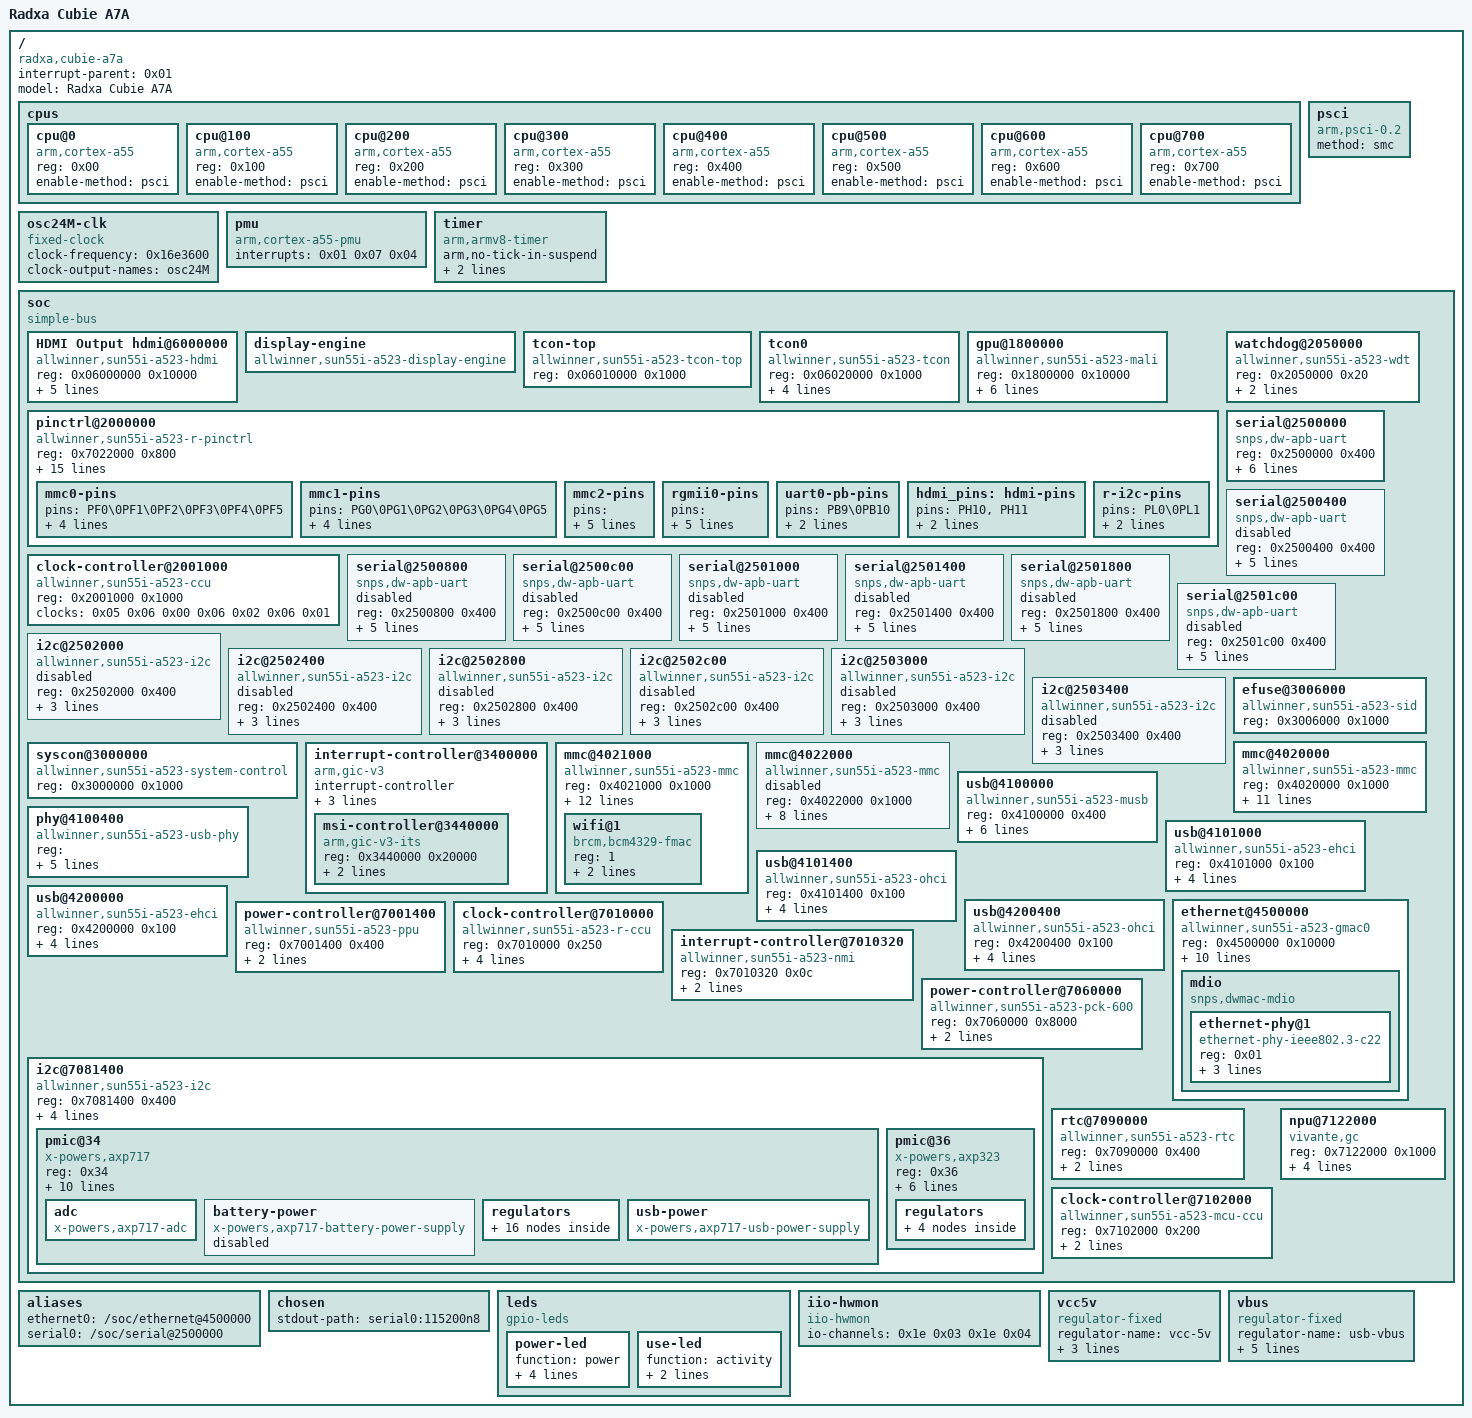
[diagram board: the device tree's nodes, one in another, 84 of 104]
/dts-v1/;

/ {
	interrupt-parent = <0x01>;
	#address-cells = <0x02>;
	#size-cells = <0x02>;
	model = "Radxa Cubie A7A";
	compatible = "radxa,cubie-a7a\0allwinner,sun60i-a733";

	cpus {
		#address-cells = <0x01>;
		#size-cells = <0x00>;

		cpu@0 {
			compatible = "arm,cortex-a55";
			device_type = "cpu";
			reg = <0x00>;
			enable-method = "psci";
		};

		cpu@100 {
			compatible = "arm,cortex-a55";
			device_type = "cpu";
			reg = <0x100>;
			enable-method = "psci";
		};

		cpu@200 {
			compatible = "arm,cortex-a55";
			device_type = "cpu";
			reg = <0x200>;
			enable-method = "psci";
		};

		cpu@300 {
			compatible = "arm,cortex-a55";
			device_type = "cpu";
			reg = <0x300>;
			enable-method = "psci";
		};

		cpu@400 {
			compatible = "arm,cortex-a55";
			device_type = "cpu";
			reg = <0x400>;
			enable-method = "psci";
		};

		cpu@500 {
			compatible = "arm,cortex-a55";
			device_type = "cpu";
			reg = <0x500>;
			enable-method = "psci";
		};

		cpu@600 {
			compatible = "arm,cortex-a55";
			device_type = "cpu";
			reg = <0x600>;
			enable-method = "psci";
		};

		cpu@700 {
			compatible = "arm,cortex-a55";
			device_type = "cpu";
			reg = <0x700>;
			enable-method = "psci";
		};
	};

	osc24M-clk {
		#clock-cells = <0x00>;
		compatible = "fixed-clock";
		clock-frequency = <0x16e3600>;
		clock-output-names = "osc24M";
		phandle = <0x05>;
	};

	pmu {
		compatible = "arm,cortex-a55-pmu";
		interrupts = <0x01 0x07 0x04>;
	};

	psci {
		compatible = "arm,psci-0.2";
		method = "smc";
	};

	timer {
		compatible = "arm,armv8-timer";
		arm,no-tick-in-suspend;
		interrupts = <0x01 0x0d 0x04 0x01 0x0e 0x04 0x01 0x0b 0x04 0x01 0x0a 0x04>;
	};

	soc {
		compatible = "simple-bus";
		#address-cells = <1>;
		#size-cells = <1>;
		ranges = <0x00 0x00 0x00 0x40000000>;

	HDMI Output
        hdmi@6000000 {
            compatible = "allwinner,sun55i-a523-hdmi";
            reg = <0x06000000 0x10000>;
            interrupts = <0 48 4>;
            clocks = <&ccu 144>;
            resets = <&ccu 96>;
            status = "okay";
            vdd-supply = <&vcc_hdmi>;
            pinctrl-names = "default";
            pinctrl-0 = <&hdmi_pins>;
        };

        display-engine {
            compatible = "allwinner,sun55i-a523-display-engine";
            status = "okay";
        };

        tcon-top {
            compatible = "allwinner,sun55i-a523-tcon-top";
            reg = <0x06010000 0x1000>;
            status = "okay";
        };

        tcon0 {
            compatible = "allwinner,sun55i-a523-tcon";
            reg = <0x06020000 0x1000>;
            interrupts = <0 49 4>;
            clocks = <&ccu 145>;
            resets = <&ccu 97>;
            status = "okay";
            vdd-supply = <&vcc_hdmi>;
		};
		
		gpu@1800000 {
			compatible = "allwinner,sun55i-a523-mali\0arm,mali-valhall-jm";
			reg = <0x1800000 0x10000>;
			interrupts = <0x00 0x75 0x04 0x00 0x76 0x04 0x00 0x77 0x04>;
			interrupt-names = "job\0mmu\0gpu";
			clocks = <0x02 0x33 0x02 0x34>;
			clock-names = "core\0bus";
			power-domains = <0x03 0x01>;
			resets = <0x02 0x06>;
			status = "okay";
			mali-supply = <0x04>;
		};

		pinctrl@2000000 {
			compatible = "allwinner,sun55i-a523-pinctrl";
			reg = <0x2000000 0x800>;
			interrupts = <0x00 0x45 0x04 0x00 0x47 0x04 0x00 0x49 0x04 0x00 0x4b 0x04 0x00 0x4d 0x04 0x00 0x4f 0x04 0x00 0x51 0x04 0x00 0x53 0x04 0x00 0x55 0x04 0x00 0x8c 0x04>;
			clocks = <0x02 0x2b 0x05 0x06 0x00>;
			clock-names = "apb\0hosc\0losc";
			gpio-controller;
			#gpio-cells = <0x03>;
			interrupt-controller;
			#interrupt-cells = <0x03>;
			vcc-pb-supply = <0x07>;
			vcc-pc-supply = <0x08>;
			vcc-pd-supply = <0x07>;
			vcc-pe-supply = <0x09>;
			vcc-pf-supply = <0x07>;
			vcc-pg-supply = <0x0a>;
			vcc-ph-supply = <0x07>;
			vcc-pi-supply = <0x07>;
			vcc-pj-supply = <0x0b>;
			vcc-pk-supply = <0x08>;
			phandle = <0x0e>;

			mmc0-pins {
				pins = "PF0\0PF1\0PF2\0PF3\0PF4\0PF5";
				allwinner,pinmux = <0x02>;
				function = "mmc0";
				drive-strength = <0x1e>;
				bias-pull-up;
				phandle = <0x0d>;
			};

			mmc1-pins {
				pins = "PG0\0PG1\0PG2\0PG3\0PG4\0PG5";
				allwinner,pinmux = <0x02>;
				function = "mmc1";
				drive-strength = <0x1e>;
				bias-pull-up;
				phandle = <0x0f>;
			};

			mmc2-pins {
				pins = "PC0\0PC1\0PC5\0PC6\0PC8\0PC9\0PC10\0PC11\0PC13\0PC14\0PC15\0PC16";
				allwinner,pinmux = <0x03>;
				function = "mmc2";
				drive-strength = <0x1e>;
				bias-pull-up;
				phandle = <0x10>;
			};

			rgmii0-pins {
				pins = "PH0\0PH1\0PH2\0PH3\0PH4\0PH5\0PH6\0PH7\0PH9\0PH10\0PH14\0PH15\0PH16\0PH17\0PH18";
				allwinner,pinmux = <0x05>;
				function = "gmac0";
				drive-strength = <0x28>;
				bias-disable;
				phandle = <0x14>;
			};

			uart0-pb-pins {
				pins = "PB9\0PB10";
				allwinner,pinmux = <0x02>;
				function = "uart0";
				phandle = <0x0c>;
			};
		};

		clock-controller@2001000 {
			compatible = "allwinner,sun55i-a523-ccu";
			reg = <0x2001000 0x1000>;
			clocks = <0x05 0x06 0x00 0x06 0x02 0x06 0x01>;
			clock-names = "hosc\0losc\0iosc\0losc-fanout";
			#clock-cells = <0x01>;
			#reset-cells = <0x01>;
			phandle = <0x02>;
		};

		watchdog@2050000 {
			compatible = "allwinner,sun55i-a523-wdt";
			reg = <0x2050000 0x20>;
			interrupts = <0x00 0x3f 0x04>;
			clocks = <0x05 0x06 0x00>;
			clock-names = "hosc\0losc";
			status = "okay";
		};

		serial@2500000 {
			compatible = "snps,dw-apb-uart";
			reg = <0x2500000 0x400>;
			interrupts = <0x00 0x02 0x04>;
			reg-shift = <0x02>;
			reg-io-width = <0x04>;
			clocks = <0x02 0x5b>;
			resets = <0x02 0x17>;
			status = "okay";
			pinctrl-names = "default";
			pinctrl-0 = <0x0c>;
		};

		serial@2500400 {
			compatible = "snps,dw-apb-uart";
			reg = <0x2500400 0x400>;
			interrupts = <0x00 0x03 0x04>;
			reg-shift = <0x02>;
			reg-io-width = <0x04>;
			clocks = <0x02 0x5c>;
			resets = <0x02 0x18>;
			status = "disabled";
		};

		serial@2500800 {
			compatible = "snps,dw-apb-uart";
			reg = <0x2500800 0x400>;
			interrupts = <0x00 0x04 0x04>;
			reg-shift = <0x02>;
			reg-io-width = <0x04>;
			clocks = <0x02 0x5d>;
			resets = <0x02 0x19>;
			status = "disabled";
		};

		serial@2500c00 {
			compatible = "snps,dw-apb-uart";
			reg = <0x2500c00 0x400>;
			interrupts = <0x00 0x05 0x04>;
			reg-shift = <0x02>;
			reg-io-width = <0x04>;
			clocks = <0x02 0x5e>;
			resets = <0x02 0x1a>;
			status = "disabled";
		};

		serial@2501000 {
			compatible = "snps,dw-apb-uart";
			reg = <0x2501000 0x400>;
			interrupts = <0x00 0x06 0x04>;
			reg-shift = <0x02>;
			reg-io-width = <0x04>;
			clocks = <0x02 0x5f>;
			resets = <0x02 0x1b>;
			status = "disabled";
		};

		serial@2501400 {
			compatible = "snps,dw-apb-uart";
			reg = <0x2501400 0x400>;
			interrupts = <0x00 0x07 0x04>;
			reg-shift = <0x02>;
			reg-io-width = <0x04>;
			clocks = <0x02 0x60>;
			resets = <0x02 0x1c>;
			status = "disabled";
		};

		serial@2501800 {
			compatible = "snps,dw-apb-uart";
			reg = <0x2501800 0x400>;
			interrupts = <0x00 0x08 0x04>;
			reg-shift = <0x02>;
			reg-io-width = <0x04>;
			clocks = <0x02 0x61>;
			resets = <0x02 0x1d>;
			status = "disabled";
		};

		serial@2501c00 {
			compatible = "snps,dw-apb-uart";
			reg = <0x2501c00 0x400>;
			interrupts = <0x00 0x09 0x04>;
			reg-shift = <0x02>;
			reg-io-width = <0x04>;
			clocks = <0x02 0x62>;
			resets = <0x02 0x1e>;
			status = "disabled";
		};

		i2c@2502000 {
			compatible = "allwinner,sun55i-a523-i2c\0allwinner,sun8i-v536-i2c\0allwinner,sun6i-a31-i2c";
			reg = <0x2502000 0x400>;
			interrupts = <0x00 0x0a 0x04>;
			clocks = <0x02 0x63>;
			resets = <0x02 0x1f>;
			status = "disabled";
			#address-cells = <0x01>;
			#size-cells = <0x00>;
		};

		i2c@2502400 {
			compatible = "allwinner,sun55i-a523-i2c\0allwinner,sun8i-v536-i2c\0allwinner,sun6i-a31-i2c";
			reg = <0x2502400 0x400>;
			interrupts = <0x00 0x0b 0x04>;
			clocks = <0x02 0x64>;
			resets = <0x02 0x20>;
			status = "disabled";
			#address-cells = <0x01>;
			#size-cells = <0x00>;
		};

		i2c@2502800 {
			compatible = "allwinner,sun55i-a523-i2c\0allwinner,sun8i-v536-i2c\0allwinner,sun6i-a31-i2c";
			reg = <0x2502800 0x400>;
			interrupts = <0x00 0x0c 0x04>;
			clocks = <0x02 0x65>;
			resets = <0x02 0x21>;
			status = "disabled";
			#address-cells = <0x01>;
			#size-cells = <0x00>;
		};

		i2c@2502c00 {
			compatible = "allwinner,sun55i-a523-i2c\0allwinner,sun8i-v536-i2c\0allwinner,sun6i-a31-i2c";
			reg = <0x2502c00 0x400>;
			interrupts = <0x00 0x0d 0x04>;
			clocks = <0x02 0x66>;
			resets = <0x02 0x22>;
			status = "disabled";
			#address-cells = <0x01>;
			#size-cells = <0x00>;
		};

		i2c@2503000 {
			compatible = "allwinner,sun55i-a523-i2c\0allwinner,sun8i-v536-i2c\0allwinner,sun6i-a31-i2c";
			reg = <0x2503000 0x400>;
			interrupts = <0x00 0x0e 0x04>;
			clocks = <0x02 0x67>;
			resets = <0x02 0x23>;
			status = "disabled";
			#address-cells = <0x01>;
			#size-cells = <0x00>;
		};

		i2c@2503400 {
			compatible = "allwinner,sun55i-a523-i2c\0allwinner,sun8i-v536-i2c\0allwinner,sun6i-a31-i2c";
			reg = <0x2503400 0x400>;
			interrupts = <0x00 0x0f 0x04>;
			clocks = <0x02 0x68>;
			resets = <0x02 0x24>;
			status = "disabled";
			#address-cells = <0x01>;
			#size-cells = <0x00>;
		};

		syscon@3000000 {
			compatible = "allwinner,sun55i-a523-system-control\0allwinner,sun50i-a64-system-control";
			reg = <0x3000000 0x1000>;
			#address-cells = <0x01>;
			#size-cells = <0x01>;
			ranges;
			phandle = <0x15>;
		};

		efuse@3006000 {
			compatible = "allwinner,sun55i-a523-sid\0allwinner,sun50i-a64-sid";
			reg = <0x3006000 0x1000>;
			#address-cells = <0x01>;
			#size-cells = <0x01>;
		};

		interrupt-controller@3400000 {
			compatible = "arm,gic-v3";
			#address-cells = <0x01>;
			#interrupt-cells = <0x03>;
			#size-cells = <0x01>;
			ranges;
			interrupt-controller;
			reg = <0x3400000 0x10000 0x3460000 0x100000>;
			interrupts = <0x01 0x09 0x04>;
			dma-noncoherent;
			phandle = <0x01>;

			msi-controller@3440000 {
				compatible = "arm,gic-v3-its";
				reg = <0x3440000 0x20000>;
				msi-controller;
				#msi-cells = <0x01>;
				dma-noncoherent;
			};
		};

		mmc@4020000 {
			compatible = "allwinner,sun55i-a523-mmc\0allwinner,sun20i-d1-mmc";
			reg = <0x4020000 0x1000>;
			clocks = <0x02 0x58 0x02 0x54>;
			clock-names = "ahb\0mmc";
			resets = <0x02 0x13>;
			reset-names = "ahb";
			interrupts = <0x00 0x28 0x04>;
			pinctrl-names = "default";
			pinctrl-0 = <0x0d>;
			status = "okay";
			max-frequency = <0x8f0d180>;
			cap-sd-highspeed;
			cap-mmc-highspeed;
			cap-sdio-irq;
			#address-cells = <0x01>;
			#size-cells = <0x00>;
			vmmc-supply = <0x07>;
			cd-gpios = <0x0e 0x05 0x06 0x11>;
			bus-width = <0x04>;
		};

			Wi-Fi 6 via SDIO (Quectel FCU760K)
        mmc@4021000 {
            compatible = "allwinner,sun55i-a523-mmc", "allwinner,sun20i-d1-mmc";
            reg = <0x4021000 0x1000>;
            clocks = <&ccu 89>, <&ccu 85>;
            clock-names = "ahb", "mmc";
            resets = <&ccu 20>;
            reset-names = "ahb";
            interrupts = <0 41 4>;
            pinctrl-names = "default";
            pinctrl-0 = <&mmc1_pins>;
            status = "okay";
            max-frequency = <0x8f0d180>;
            cap-sd-highspeed;
            cap-mmc-highspeed;
            cap-sdio-irq;
            bus-width = <4>;
            non-removable;
            keep-power-in-suspend;
            vmmc-supply = <&vcc_pg_iowifi>;

            wifi@1 {
                reg = <1>;
                compatible = "brcm,bcm4329-fmac";
                interrupt-parent = <&pio>;
                interrupts = <0 6 4>; // Adjust GPIO if needed
            };
        };


		mmc@4022000 {
			compatible = "allwinner,sun55i-a523-mmc\0allwinner,sun20i-d1-mmc";
			reg = <0x4022000 0x1000>;
			clocks = <0x02 0x5a 0x02 0x56>;
			clock-names = "ahb\0mmc";
			resets = <0x02 0x15>;
			reset-names = "ahb";
			interrupts = <0x00 0x2a 0x04>;
			pinctrl-names = "default";
			pinctrl-0 = <0x10>;
			status = "disabled";
			max-frequency = <0x8f0d180>;
			cap-sd-highspeed;
			cap-mmc-highspeed;
			cap-sdio-irq;
			#address-cells = <0x01>;
			#size-cells = <0x00>;
		};

		usb@4100000 {
			compatible = "allwinner,sun55i-a523-musb\0allwinner,sun8i-a33-musb";
			reg = <0x4100000 0x400>;
			interrupts = <0x00 0x1d 0x04>;
			interrupt-names = "mc";
			clocks = <0x02 0x85>;
			resets = <0x02 0x37>;
			extcon = <0x11 0x00>;
			phys = <0x11 0x00>;
			phy-names = "usb";
			status = "okay";
			dr_mode = "peripheral";
		};

		phy@4100400 {
			compatible = "allwinner,sun55i-a523-usb-phy\0allwinner,sun20i-d1-usb-phy";
			reg = <0x4100400 0x100 0x4101800 0x100 0x4200800 0x100>;
			reg-names = "phy_ctrl\0pmu0\0pmu1";
			clocks = <0x05 0x05>;
			clock-names = "usb0_phy\0usb1_phy";
			resets = <0x02 0x31 0x02 0x32>;
			reset-names = "usb0_reset\0usb1_reset";
			status = "okay";
			#phy-cells = <0x01>;
			usb0_vbus-supply = <0x12>;
			usb1_vbus-supply = <0x13>;
			phandle = <0x11>;
		};

		usb@4101000 {
			compatible = "allwinner,sun55i-a523-ehci\0generic-ehci";
			reg = <0x4101000 0x100>;
			interrupts = <0x00 0x1e 0x04>;
			clocks = <0x02 0x81 0x02 0x83 0x02 0x7f>;
			resets = <0x02 0x33 0x02 0x35>;
			phys = <0x11 0x00>;
			phy-names = "usb";
			status = "okay";
		};

		usb@4101400 {
			compatible = "allwinner,sun55i-a523-ohci\0generic-ohci";
			reg = <0x4101400 0x100>;
			interrupts = <0x00 0x1f 0x04>;
			clocks = <0x02 0x81 0x02 0x7f>;
			resets = <0x02 0x33>;
			phys = <0x11 0x00>;
			phy-names = "usb";
			status = "okay";
		};

		usb@4200000 {
			compatible = "allwinner,sun55i-a523-ehci\0generic-ehci";
			reg = <0x4200000 0x100>;
			interrupts = <0x00 0x20 0x04>;
			clocks = <0x02 0x82 0x02 0x84 0x02 0x80>;
			resets = <0x02 0x34 0x02 0x36>;
			phys = <0x11 0x01>;
			phy-names = "usb";
			status = "okay";
		};

		usb@4200400 {
			compatible = "allwinner,sun55i-a523-ohci\0generic-ohci";
			reg = <0x4200400 0x100>;
			interrupts = <0x00 0x21 0x04>;
			clocks = <0x02 0x82 0x02 0x80>;
			resets = <0x02 0x34>;
			phys = <0x11 0x01>;
			phy-names = "usb";
			status = "okay";
		};

		ethernet@4500000 {
			compatible = "allwinner,sun55i-a523-gmac0\0allwinner,sun50i-a64-emac";
			reg = <0x4500000 0x10000>;
			clocks = <0x02 0x74>;
			clock-names = "stmmaceth";
			resets = <0x02 0x2a>;
			reset-names = "stmmaceth";
			interrupts = <0x00 0x2e 0x04>;
			interrupt-names = "macirq";
			pinctrl-names = "default";
			pinctrl-0 = <0x14>;
			syscon = <0x15>;
			status = "okay";
			phy-mode = "rgmii-id";
			phy-handle = <0x16>;
			phy-supply = <0x07>;
			allwinner,tx-delay-ps = <0x12c>;
			allwinner,rx-delay-ps = <0x190>;

			mdio {
				compatible = "snps,dwmac-mdio";
				#address-cells = <0x01>;
				#size-cells = <0x00>;

				ethernet-phy@1 {
					compatible = "ethernet-phy-ieee802.3-c22";
					reg = <0x01>;
					reset-gpios = <0x0e 0x07 0x08 0x01>;
					reset-assert-us = <0x2710>;
					reset-deassert-us = <0x249f0>;
					phandle = <0x16>;
				};
			};
		};

		power-controller@7001400 {
			compatible = "allwinner,sun55i-a523-ppu";
			reg = <0x7001400 0x400>;
			clocks = <0x17 0x14>;
			resets = <0x17 0x0b>;
			#power-domain-cells = <0x01>;
			phandle = <0x1c>;
		};

		clock-controller@7010000 {
			compatible = "allwinner,sun55i-a523-r-ccu";
			reg = <0x7010000 0x250>;
			clocks = <0x05 0x06 0x00 0x06 0x02 0x02 0x08 0x02 0x23>;
			clock-names = "hosc\0losc\0iosc\0pll-periph\0pll-audio";
			#clock-cells = <0x01>;
			#reset-cells = <0x01>;
			assigned-clocks = <0x17 0x00 0x17 0x01>;
			assigned-clock-rates = <0xbebc200 0x5f5e100>;
			phandle = <0x17>;
		};

		interrupt-controller@7010320 {
			compatible = "allwinner,sun55i-a523-nmi";
			reg = <0x7010320 0x0c>;
			interrupt-controller;
			#interrupt-cells = <0x02>;
			interrupts = <0x00 0x94 0x04>;
			phandle = <0x1a>;
		};

		pinctrl@2000000 {
			compatible = "allwinner,sun55i-a523-r-pinctrl";
			reg = <0x7022000 0x800>;
			interrupts = <0x00 0x9f 0x04 0x00 0xa1 0x04>;
			clocks = <0x17 0x01 0x05 0x06 0x00>;
			clock-names = "apb\0hosc\0losc";
			gpio-controller;
			#gpio-cells = <0x03>;
			interrupt-controller;
			#interrupt-cells = <0x03>;
			vcc-pm-supply = <0x18>;
			phandle = <0x1d>;
		    
		hdmi_pins: hdmi-pins {
        	pins = "PH10", "PH11";
        	function = "hdmi";
        	bias-disable;
    	};
	

			r-i2c-pins {
				pins = "PL0\0PL1";
				allwinner,pinmux = <0x02>;
				function = "r_i2c0";
				phandle = <0x19>;
			};
		};

		power-controller@7060000 {
			compatible = "allwinner,sun55i-a523-pck-600";
			reg = <0x7060000 0x8000>;
			clocks = <0x17 0x13>;
			resets = <0x17 0x0f>;
			#power-domain-cells = <0x01>;
			phandle = <0x03>;
		};

		i2c@7081400 {
			compatible = "allwinner,sun55i-a523-i2c\0allwinner,sun8i-v536-i2c\0allwinner,sun6i-a31-i2c";
			reg = <0x7081400 0x400>;
			interrupts = <0x00 0xa4 0x04>;
			clocks = <0x17 0x10>;
			resets = <0x17 0x08>;
			pinctrl-names = "default";
			pinctrl-0 = <0x19>;
			status = "okay";
			#address-cells = <0x01>;
			#size-cells = <0x00>;

			pmic@34 {
				compatible = "x-powers,axp717";
				reg = <0x34>;
				interrupt-controller;
				#interrupt-cells = <0x01>;
				interrupt-parent = <0x1a>;
				interrupts = <0x00 0x08>;
				vin1-supply = <0x12>;
				vin2-supply = <0x12>;
				vin3-supply = <0x12>;
				vin4-supply = <0x12>;
				aldoin-supply = <0x12>;
				bldoin-supply = <0x12>;
				cldoin-supply = <0x12>;

				adc {
					compatible = "x-powers,axp717-adc";
					#io-channel-cells = <0x01>;
					phandle = <0x1e>;
				};

				battery-power {
					compatible = "x-powers,axp717-battery-power-supply";
					status = "disabled";
				};

				regulators {

					dcdc1 {
						regulator-always-on;
						regulator-min-microvolt = <0xdbba0>;
						regulator-max-microvolt = <0x11b340>;
						regulator-name = "vdd-cpul";
					};

					dcdc2 {
						regulator-always-on;
						regulator-min-microvolt = <0xe09c0>;
						regulator-max-microvolt = <0xe09c0>;
						regulator-name = "vdd-gpu-sys";
						phandle = <0x04>;
					};

					dcdc3 {
						regulator-always-on;
						regulator-min-microvolt = <0x10c8e0>;
						regulator-max-microvolt = <0x10c8e0>;
						regulator-name = "vdd-dram";
					};

					aldo1 {
					};

					aldo2 {
						regulator-min-microvolt = <0x1b7740>;
						regulator-max-microvolt = <0x1b7740>;
						regulator-name = "vcc-pe";
						phandle = <0x09>;
					};

					aldo3 {
						regulator-always-on;
						regulator-min-microvolt = <0x325aa0>;
						regulator-max-microvolt = <0x325aa0>;
						regulator-name = "vcc-pl-usb";
						phandle = <0x18>;
					};

					aldo4 {
						regulator-always-on;
						regulator-min-microvolt = <0x1b7740>;
						regulator-max-microvolt = <0x1b7740>;
						regulator-name = "vcc-pll-dxco-avcc";
					};

					bldo1 {
						regulator-min-microvolt = <0x1b7740>;
						regulator-max-microvolt = <0x1b7740>;
						regulator-name = "vcc-pg-iowifi";
						phandle = <0x0a>;
					};

					bldo2 {
						regulator-always-on;
						regulator-min-microvolt = <0x1b7740>;
						regulator-max-microvolt = <0x1b7740>;
						regulator-name = "vcc-pm-lpddr4";
					};

					bldo3 {
						regulator-min-microvolt = <0x325aa0>;
						regulator-max-microvolt = <0x325aa0>;
						regulator-name = "vcc-mipi-cam";
					};

					bldo4 {
					};

					cldo1 {
						regulator-min-microvolt = <0x1b7740>;
						regulator-max-microvolt = <0x1b7740>;
						regulator-name = "vcc-pc-and-their-dog";
						phandle = <0x08>;
					};

					cldo2 {
					};

					cldo3 {
						regulator-always-on;
						regulator-min-microvolt = <0x325aa0>;
						regulator-max-microvolt = <0x325aa0>;
						regulator-name = "vcc-io-mmc-spi-ana";
						phandle = <0x07>;
					};

					cldo4 {
						regulator-min-microvolt = <0x325aa0>;
						regulator-max-microvolt = <0x325aa0>;
						regulator-name = "vcc-pj-phy";
						phandle = <0x0b>;
					};

					cpusldo {
						regulator-always-on;
						regulator-min-microvolt = <0xdbba0>;
						regulator-max-microvolt = <0xdbba0>;
						regulator-name = "vdd-cpus";
					};
				};

				usb-power {
					compatible = "x-powers,axp717-usb-power-supply";
				};
			};

			pmic@36 {
				compatible = "x-powers,axp323";
				reg = <0x36>;
				#interrupt-cells = <0x01>;
				interrupt-controller;
				interrupt-parent = <0x1a>;
				interrupts = <0x00 0x08>;
				status = "okay";
				vin1-supply = <0x12>;
				vin2-supply = <0x12>;
				vin3-supply = <0x12>;

				regulators {

					aldo1 {
						regulator-min-microvolt = <0x1b7740>;
						regulator-max-microvolt = <0x1b7740>;
						regulator-name = "vcc-mipi-dsi";
					};

					dldo1 {
					};

					dcdc1 {
						regulator-always-on;
						regulator-min-microvolt = <0xdbba0>;
						regulator-max-microvolt = <0x11b340>;
						regulator-name = "vdd-cpub";
					};

					dcdc3 {
						regulator-always-on;
						regulator-min-microvolt = <0xdbba0>;
						regulator-max-microvolt = <0xdbba0>;
						regulator-name = "vdd-dnr";
					};
				};
			};
		};

		rtc@7090000 {
			compatible = "allwinner,sun55i-a523-rtc\0allwinner,sun50i-r329-rtc";
			reg = <0x7090000 0x400>;
			interrupts = <0x00 0x9d 0x04>;
			clocks = <0x17 0x19 0x05 0x17 0x00>;
			clock-names = "bus\0hosc\0ahb";
			#clock-cells = <0x01>;
			phandle = <0x06>;
		};

		clock-controller@7102000 {
			compatible = "allwinner,sun55i-a523-mcu-ccu";
			reg = <0x7102000 0x200>;
			clocks = <0x05 0x06 0x00 0x06 0x02 0x02 0x23 0x02 0x07 0x02 0xa9 0x02 0x2c 0x17 0x00 0x17 0x01>;
			clock-names = "hosc\0losc\0iosc\0pll-audio0-4x\0pll-periph0-300m\0dsp\0mbus\0r-ahb\0r-apb0";
			#clock-cells = <0x01>;
			#reset-cells = <0x01>;
			phandle = <0x1b>;
		};

		npu@7122000 {
			compatible = "vivante,gc";
			reg = <0x7122000 0x1000>;
			interrupts = <0x00 0xc7 0x04>;
			clocks = <0x1b 0x19 0x02 0xb3 0x1b 0x18>;
			clock-names = "bus\0core\0reg";
			resets = <0x1b 0x09>;
			power-domains = <0x1c 0x01>;
		};
	};

	aliases {
		ethernet0 = "/soc/ethernet@4500000";
		serial0 = "/soc/serial@2500000";
	};

	chosen {
		stdout-path = "serial0:115200n8";
	};

	leds {
		compatible = "gpio-leds";

		power-led {
			function = "power";
			color = <0x02>;
			gpios = <0x1d 0x00 0x04 0x01>;
			default-state = "on";
			linux,default-trigger = "heartbeat";
		};

		use-led {
			function = "activity";
			color = <0x03>;
			gpios = <0x1d 0x00 0x05 0x01>;
		};
	};

	iio-hwmon {
		compatible = "iio-hwmon";
		io-channels = <0x1e 0x03 0x1e 0x04>;
	};

	vcc5v {
		compatible = "regulator-fixed";
		regulator-name = "vcc-5v";
		regulator-min-microvolt = <0x4c4b40>;
		regulator-max-microvolt = <0x4c4b40>;
		regulator-always-on;
		phandle = <0x12>;
	};

	vbus {
		compatible = "regulator-fixed";
		regulator-name = "usb-vbus";
		regulator-min-microvolt = <0x4c4b40>;
		regulator-max-microvolt = <0x4c4b40>;
		vin-supply = <0x12>;
		gpio = <0x1d 0x00 0x08 0x00>;
		enable-active-high;
		phandle = <0x13>;
	};
};
